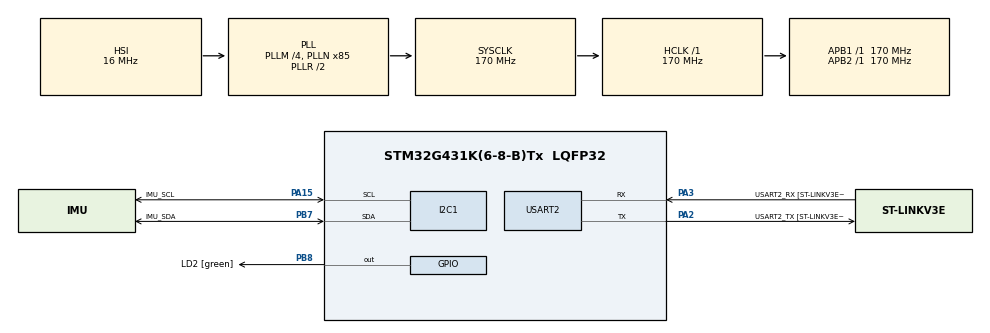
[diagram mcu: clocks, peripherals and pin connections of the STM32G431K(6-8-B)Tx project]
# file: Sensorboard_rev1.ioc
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Dma.Request0=USART2_RX
Dma.USART2_RX.0.Direction=DMA_PERIPH_TO_MEMORY
Dma.USART2_RX.0.EventEnable=DISABLE
Dma.USART2_RX.0.Instance=DMA1_Channel1
Dma.USART2_RX.0.MemDataAlignment=DMA_MDATAALIGN_BYTE
Dma.USART2_RX.0.MemInc=DMA_MINC_ENABLE
Dma.USART2_RX.0.Mode=DMA_NORMAL
Dma.USART2_RX.0.PeriphDataAlignment=DMA_PDATAALIGN_BYTE
Dma.USART2_RX.0.PeriphInc=DMA_PINC_DISABLE
Dma.USART2_RX.0.Polarity=HAL_DMAMUX_REQ_GEN_RISING
Dma.USART2_RX.0.Priority=DMA_PRIORITY_LOW
Dma.USART2_RX.0.RequestNumber=1
Dma.USART2_RX.0.SignalID=NONE
Dma.USART2_RX.0.SyncEnable=DISABLE
Dma.USART2_RX.0.SyncPolarity=HAL_DMAMUX_SYNC_NO_EVENT
Dma.USART2_RX.0.SyncRequestNumber=1
Dma.USART2_RX.0.SyncSignalID=NONE
I2C1.Timing=0x30A0A7FB
Mcu.Family=STM32G4
Mcu.Name=STM32G431K(6-8-B)Tx
Mcu.Package=LQFP32
NVIC.DMA1_Channel1_IRQn=true\:0\:0\:false\:false\:true\:false\:true\:true
NVIC.PriorityGroup=NVIC_PRIORITYGROUP_4
NVIC.USART2_IRQn=true\:0\:0\:false\:false\:true\:true\:true\:true
PA13.GPIO_Label=T_SWDIO
PA13.Mode=Serial_Wire
PA13.Signal=SYS_JTMS-SWDIO
PA14.GPIO_Label=T_SWCLK
PA14.Mode=Serial_Wire
PA14.Signal=SYS_JTCK-SWCLK
PA15.GPIO_Label=IMU_SCL
PA15.Mode=I2C
PA15.Signal=I2C1_SCL
PA2.GPIO_Label=USART2_TX [ST-LINKV3E_VCP_RX]
PA2.Mode=Asynchronous
PA2.Signal=USART2_TX
PA3.GPIO_Label=USART2_RX [ST-LINKV3E_VCP_TX]
PA3.Mode=Asynchronous
PA3.Signal=USART2_RX
PB3.GPIO_Label=T_SWO
PB3.Signal=SYS_JTDO-SWO
PB7.GPIO_Label=IMU_SDA
PB7.Mode=I2C
PB7.Signal=I2C1_SDA
PB8-BOOT0.GPIO_Label=LD2 [green]
PB8-BOOT0.Signal=GPIO_Output
ProjectManager.HeapSize=0x200
ProjectManager.StackSize=0x400
ProjectManager.TargetToolchain=STM32CubeIDE
RCC.ADC12Freq_Value=170000000
RCC.AHBFreq_Value=170000000
RCC.APB1Freq_Value=170000000
RCC.APB1TimFreq_Value=170000000
RCC.APB2Freq_Value=170000000
RCC.APB2TimFreq_Value=170000000
RCC.CortexFreq_Value=170000000
RCC.EXTERNAL_CLOCK_VALUE=12288000
RCC.HCLKFreq_Value=170000000
RCC.HSE_VALUE=8000000
RCC.HSI48_VALUE=48000000
RCC.HSI_VALUE=16000000
RCC.LSE_VALUE=32768
RCC.PLLM=RCC_PLLM_DIV4
RCC.PLLN=85
RCC.SYSCLKFreq_VALUE=170000000
RCC.SYSCLKSource=RCC_SYSCLKSOURCE_PLLCLK
RCC.USBFreq_Value=170000000
RCC.VCOOutputFreq_Value=340000000
USART2.VirtualMode-Asynchronous=VM_ASYNC
USART2.WordLength=WORDLENGTH_8B
board=NUCLEO-G431KB

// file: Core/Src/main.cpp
/* USER CODE BEGIN Header */
/**
  ******************************************************************************
  * @file           : main.c
  * @brief          : Main program body
  ******************************************************************************
  * @attention
  *
  * Copyright (c) 2023 STMicroelectronics.
  * All rights reserved.
  *
  * This software is licensed under terms that can be found in the LICENSE file
  * in the root directory of this software component.
  * If no LICENSE file comes with this software, it is provided AS-IS.
  *
  ******************************************************************************
  */
/* USER CODE END Header */
#include "main.h"

/* USER CODE BEGIN Includes */
#include <stdlib.h>
#include <stdio.h>
#include <string.h>
#include <stdbool.h>

//#include "packets.h"
//#include "util.h"
//#include "imu_config.h"
/* USER CODE END Includes */

I2C_HandleTypeDef hi2c1;

UART_HandleTypeDef huart2;
DMA_HandleTypeDef hdma_usart2_rx;

/* USER CODE BEGIN PV */
uint8_t txbuffer[64] = "Hello from stm32 2!!\r\n";
uint8_t rxbuffer[1];

// Sensors

/* USER CODE END PV */

void SystemClock_Config(void);
static void MX_GPIO_Init(void);
static void MX_DMA_Init(void);
static void MX_I2C1_Init(void);
static void MX_USART2_UART_Init(void);
/* USER CODE BEGIN PFP */

//void sendmessage(const char* msg)
//{
//	HAL_UART_Transmit(&huart2, (uint8_t *)msg, strlen(msg), 100);
//}

/* USER CODE END PFP */

int main(void)
{

  /* MCU Configuration--------------------------------------------------------*/

  /* Reset of all peripherals, Initializes the Flash interface and the Systick. */
  HAL_Init();

  /* Configure the system clock */
  SystemClock_Config();

  /* Initialize all configured peripherals */
  MX_GPIO_Init();
  MX_DMA_Init();
  MX_I2C1_Init();
  MX_USART2_UART_Init();
  /* USER CODE BEGIN 2 */
  HAL_UART_Transmit(&huart2, (uint8_t *)txbuffer, sizeof(txbuffer), 100);
  HAL_UART_Receive_DMA(&huart2, rxbuffer, sizeof(rxbuffer));
  //imu_init();
	//Scan_I2C_Devices(&huart2, &hi2c1);

//	// enable temperature sensor
//	// set TEMP_EN high in CTRL_REG5_XM(24h)
//	static const uint8_t TEMP_EN = 0x80 ;
//	static const uint16_t CTRL_REG5_XM = 0x24 << 1;
//	static const uint8_t newval = 0b00011000;
//
//
//	static const uint16_t OUT_TEMP_L_XM = 0x5 << 1;
//
//	buf[0] = newval | TEMP_EN;
//	ret = HAL_I2C_Master_Transmit(&hi2c1, CTRL_REG5_XM, buf, 1, 100);
//	if ( ret != HAL_OK ) Error_Handler();

//	static const uint8_t devadd = 0x3c;
//	static const uint8_t memadd = 0x3c;
//
//	uint8_t buf1[12] = {0};
//	i2c_writeAndRead(devadd, 0x12, buf1, 1);
//	uint8_t retval = buf1[0];//0x3d
//	HAL_Delay(100);

	//HAL_I2C_Mem_Read(&hi2c1, devadd, memadd, 1, buf1, 1, 100);

//	#define REG 0x0f
//	uint8_t buffer[12];
//	buffer[0] = REG;
//	ret = HAL_I2C_Master_Receive(&hi2c1, ADDR, buffer, 1, 100);
//	if ( ret != HAL_OK ) Error_Handler();

	// 0 1 0 0 1 0 0 1

	/*
	Both OUT_TEMP_H_XM and OUT_TEMP_L_XM registers must be read.
	Temperature data is stored inside OUT_TEMP_L_XM (05h), OUT_TEMP_H_XM (06h) as
	two’s complement data in 12-bit format, right justified.
	The output data rate of the temperature sensor is set by M_ODR in CTRL_REG5_XM (24h)
	and is equal to the magnetic sensor output data rate
	 */
  /* USER CODE END 2 */
  /* Infinite loop */
  /* USER CODE BEGIN WHILE */
	while (1)
	{
		//imu_loop();
    /* USER CODE END WHILE */

//    /* USER CODE BEGIN 3 */
////		buf[0] = newval;
////		ret = HAL_I2C_Master_Transmit(&hi2c1, CTRL_REG5_XM, buf, 1, 100);
//	    if ( ret != HAL_OK ) {
//	      strcpy((char*)buf, "Error Tx\r\n");
//	    } else {
//
//	      // Read 2 bytes from the temperature register
//	    	static const uint8_t OUT_TEMP_L_XM = 0x5;
//	    	ret = HAL_I2C_Master_Receive(&hi2c1, OUT_TEMP_L_XM, buf, 2, 100);
//	      if ( ret != HAL_OK ) {
//	        strcpy((char*)buf, "Error Rx\r\n");
//	      } else {
//
//	        //Combine the bytes
//	        val = ((int16_t)buf[0] << 4) | (buf[1] >> 4);
//
//	        // Convert to 2's complement, since temperature can be negative
//	        if ( val > 0x7FF ) {
//	          val |= 0xF000;
//	        }
//
//	        // Convert to float temperature value (Celsius)
//	        temp_c = val * 0.0625;
//
//	        // Convert temperature to decimal format
//	        temp_c *= 100;
//	        sprintf((char*)buf,
//	              "%u.%u C\r\n",
//	              ((unsigned int)temp_c / 100),
//	              ((unsigned int)temp_c % 100));

	        /*
			  uint8_t xlo = buffer[0];
			  int16_t xhi = buffer[1];

			  xhi <<= 8;
			  xhi |= xlo;

			  // Shift values to create properly formed integer (low byte first)
			  temperature = xhi;
	         */
//	      }
//	    }
//
//	    // Send out buffer (temperature or error message)
//	    HAL_UART_Transmit(&huart2, buf, strlen((char*)buf), 100);
//
//	    // Wait
//	    HAL_Delay(500);

	}
  /* USER CODE END 3 */
}

void SystemClock_Config(void)
{
  RCC_OscInitTypeDef RCC_OscInitStruct = {0};
  RCC_ClkInitTypeDef RCC_ClkInitStruct = {0};

  /** Configure the main internal regulator output voltage
  */
  HAL_PWREx_ControlVoltageScaling(PWR_REGULATOR_VOLTAGE_SCALE1_BOOST);

  /** Initializes the RCC Oscillators according to the specified parameters
  * in the RCC_OscInitTypeDef structure.
  */
  RCC_OscInitStruct.OscillatorType = RCC_OSCILLATORTYPE_HSI;
  RCC_OscInitStruct.HSIState = RCC_HSI_ON;
  RCC_OscInitStruct.HSICalibrationValue = RCC_HSICALIBRATION_DEFAULT;
  RCC_OscInitStruct.PLL.PLLState = RCC_PLL_ON;
  RCC_OscInitStruct.PLL.PLLSource = RCC_PLLSOURCE_HSI;
  RCC_OscInitStruct.PLL.PLLM = RCC_PLLM_DIV4;
  RCC_OscInitStruct.PLL.PLLN = 85;
  RCC_OscInitStruct.PLL.PLLP = RCC_PLLP_DIV2;
  RCC_OscInitStruct.PLL.PLLQ = RCC_PLLQ_DIV2;
  RCC_OscInitStruct.PLL.PLLR = RCC_PLLR_DIV2;
  if (HAL_RCC_OscConfig(&RCC_OscInitStruct) != HAL_OK)
  {
    Error_Handler();
  }

  /** Initializes the CPU, AHB and APB buses clocks
  */
  RCC_ClkInitStruct.ClockType = RCC_CLOCKTYPE_HCLK|RCC_CLOCKTYPE_SYSCLK
                              |RCC_CLOCKTYPE_PCLK1|RCC_CLOCKTYPE_PCLK2;
  RCC_ClkInitStruct.SYSCLKSource = RCC_SYSCLKSOURCE_PLLCLK;
  RCC_ClkInitStruct.AHBCLKDivider = RCC_SYSCLK_DIV1;
  RCC_ClkInitStruct.APB1CLKDivider = RCC_HCLK_DIV1;
  RCC_ClkInitStruct.APB2CLKDivider = RCC_HCLK_DIV1;

  if (HAL_RCC_ClockConfig(&RCC_ClkInitStruct, FLASH_LATENCY_4) != HAL_OK)
  {
    Error_Handler();
  }
}

static void MX_I2C1_Init(void)
{

  hi2c1.Instance = I2C1;
  hi2c1.Init.Timing = 0x30A0A7FB;
  hi2c1.Init.OwnAddress1 = 0;
  hi2c1.Init.AddressingMode = I2C_ADDRESSINGMODE_7BIT;
  hi2c1.Init.DualAddressMode = I2C_DUALADDRESS_DISABLE;
  hi2c1.Init.OwnAddress2 = 0;
  hi2c1.Init.OwnAddress2Masks = I2C_OA2_NOMASK;
  hi2c1.Init.GeneralCallMode = I2C_GENERALCALL_DISABLE;
  hi2c1.Init.NoStretchMode = I2C_NOSTRETCH_DISABLE;
  if (HAL_I2C_Init(&hi2c1) != HAL_OK)
  {
    Error_Handler();
  }

  /** Configure Analogue filter
  */
  if (HAL_I2CEx_ConfigAnalogFilter(&hi2c1, I2C_ANALOGFILTER_ENABLE) != HAL_OK)
  {
    Error_Handler();
  }

  /** Configure Digital filter
  */
  if (HAL_I2CEx_ConfigDigitalFilter(&hi2c1, 0) != HAL_OK)
  {
    Error_Handler();
  }

}

static void MX_USART2_UART_Init(void)
{

  huart2.Instance = USART2;
  huart2.Init.BaudRate = 115200;
  huart2.Init.WordLength = UART_WORDLENGTH_8B;
  huart2.Init.StopBits = UART_STOPBITS_1;
  huart2.Init.Parity = UART_PARITY_NONE;
  huart2.Init.Mode = UART_MODE_TX_RX;
  huart2.Init.HwFlowCtl = UART_HWCONTROL_NONE;
  huart2.Init.OverSampling = UART_OVERSAMPLING_16;
  huart2.Init.OneBitSampling = UART_ONE_BIT_SAMPLE_DISABLE;
  huart2.Init.ClockPrescaler = UART_PRESCALER_DIV1;
  huart2.AdvancedInit.AdvFeatureInit = UART_ADVFEATURE_NO_INIT;
  if (HAL_UART_Init(&huart2) != HAL_OK)
  {
    Error_Handler();
  }
  if (HAL_UARTEx_SetTxFifoThreshold(&huart2, UART_TXFIFO_THRESHOLD_1_8) != HAL_OK)
  {
    Error_Handler();
  }
  if (HAL_UARTEx_SetRxFifoThreshold(&huart2, UART_RXFIFO_THRESHOLD_1_8) != HAL_OK)
  {
    Error_Handler();
  }
  if (HAL_UARTEx_DisableFifoMode(&huart2) != HAL_OK)
  {
    Error_Handler();
  }

}

static void MX_DMA_Init(void)
{

  /* DMA controller clock enable */
  __HAL_RCC_DMAMUX1_CLK_ENABLE();
  __HAL_RCC_DMA1_CLK_ENABLE();

  /* DMA interrupt init */
  /* DMA1_Channel1_IRQn interrupt configuration */
  HAL_NVIC_SetPriority(DMA1_Channel1_IRQn, 0, 0);
  HAL_NVIC_EnableIRQ(DMA1_Channel1_IRQn);

}

static void MX_GPIO_Init(void)
{
  GPIO_InitTypeDef GPIO_InitStruct = {0};

  /* GPIO Ports Clock Enable */
  __HAL_RCC_GPIOA_CLK_ENABLE();
  __HAL_RCC_GPIOB_CLK_ENABLE();

  /*Configure GPIO pin Output Level */
  HAL_GPIO_WritePin(LD2_GPIO_Port, LD2_Pin, GPIO_PIN_RESET);

  /*Configure GPIO pin : LD2_Pin */
  GPIO_InitStruct.Pin = LD2_Pin;
  GPIO_InitStruct.Mode = GPIO_MODE_OUTPUT_PP;
  GPIO_InitStruct.Pull = GPIO_NOPULL;
  GPIO_InitStruct.Speed = GPIO_SPEED_FREQ_LOW;
  HAL_GPIO_Init(LD2_GPIO_Port, &GPIO_InitStruct);

}

/* USER CODE BEGIN 4 */
//PacketHandler packet_handler;

void HAL_UART_RxCpltCallback(UART_HandleTypeDef *huart)
{
	// only uart2 should be parsed
	if(huart->Instance != USART2)
	{
		return;
	}
	//packet_handler.processData(rxbuffer, sizeof(rxbuffer));
}

/* USER CODE END 4 */

void Error_Handler(void)
{
  __disable_irq();
  while (1)
  {
  }
}
